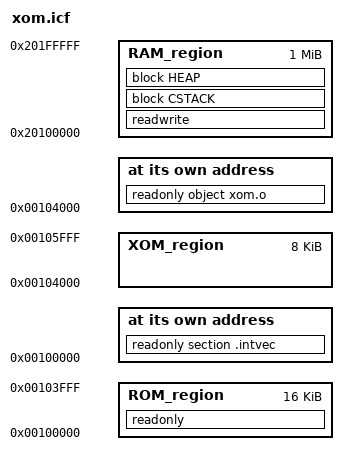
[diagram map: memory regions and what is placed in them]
/*###ICF### Section handled by ICF editor, don't touch! ****/
/*-Editor annotation file-*/
/* IcfEditorFile="$TOOLKIT_DIR$\config\ide\IcfEditor\cortex_v1_0.xml" */
/*-Specials-*/
define symbol __ICFEDIT_intvec_start__ = 0x00100000;

/*-Memory Regions-*/
define symbol __ICFEDIT_region_ROM_start__      = 0x00100000;
define symbol __ICFEDIT_region_ROM_end__        = 0x00103FFF;
define symbol __ICFEDIT_region_XOM_start__      = 0x00104000;
define symbol __ICFEDIT_region_XOM_end__        = 0x00105FFF;
define symbol __ICFEDIT_region_Invalid_start__  = 0x0;
define symbol __ICFEDIT_region_Invalid_end__    = 0x0;
define symbol __ICFEDIT_region_RAM_start__      = 0x20100000;
define symbol __ICFEDIT_region_RAM_end__        = 0x201FFFFF;

/*-Sizes-*/
define symbol __ICFEDIT_size_cstack__ = 0x00000800;
define symbol __ICFEDIT_size_heap__   = 0x00000800;
/**** End of ICF editor section. ###ICF###*/

define memory mem with size = 4G;
define region ROM_region  = mem:[from __ICFEDIT_region_ROM_start__  to __ICFEDIT_region_ROM_end__ ];
define region XOM_region  = mem:[from __ICFEDIT_region_XOM_start__  to __ICFEDIT_region_XOM_end__ ];
define region RAM_region  = mem:[from __ICFEDIT_region_RAM_start__  to __ICFEDIT_region_RAM_end__ ];
define region Invalid     = mem:[from __ICFEDIT_region_Invalid_start__  to __ICFEDIT_region_Invalid_end__ ];

define block CSTACK with alignment = 8, size = __ICFEDIT_size_cstack__ { };
define block HEAP   with alignment = 8, size = __ICFEDIT_size_heap__   { };

initialize by copy { readwrite };

do not initialize  { section .noinit, section .bss.tensor_arena, section .bss.NoInit.activation_buf_sram };

place at address mem:__ICFEDIT_intvec_start__     { readonly section .intvec };
/* Enable "No data reads in code memory" option of xom.c */
place at address mem:__ICFEDIT_region_XOM_start__ { readonly object xom.o };

place in ROM_region  { readonly };
place in RAM_region  { readwrite, block CSTACK, block HEAP };
/* We should not use RW / ZI in XOM. Add an empty section to detect them. */
place in Invalid     { readwrite object xom.o };
